# S32K322_M7 register map
Vendor: NXP Semiconductors; File version: 1.0
CPU: CM7 r0p1, little endian, MPU, FPU, VTOR, 4 interrupt priority bits
Registers are 32-bit, read-write, reset 0x0 unless marked. A register's access mark holds for its fields unless they carry their own. Offsets are from the block's base; [hi:lo] are bit positions; {n}, {i} and the like mark numbered series.

## DMAMUX_0 — DMAMUX
Base 0x40280000
Same registers: DMAMUX_1 0x40284000
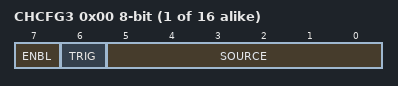
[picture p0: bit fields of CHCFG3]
0x00 CHCFG{x} (x=3,2,1,0,7,6,5,4,11,10,9,8,15,14,13,12; step 0x1) 8-bit — Channel Configuration register
  [7] ENBL — DMA Channel Enable
    0=DISABLE (DMA channel is disabled. This mode is primarily used during configuration of the DMAMUX. The DMA has separate channel enables/disables, which should be used to disable or reconfigure a DMA channel.); 1=ENABLE (DMA channel is enabled)
  [6] TRIG — DMA Channel Trigger Enable
    0=DISABLE (Triggering is disabled. If triggering is disabled and ENBL is set, the DMA Channel will simply route the specified source to the DMA channel. (Normal mode)); 1=ENABLE (Triggering is enabled. If triggering is enabled and ENBL is set, the DMAMUX is in Periodic Trigger mode.)
  [5:0] SOURCE — DMA Channel Source (Slot)

## RTC
Base 0x40288000
0x00 RTCSUPV reset 0x80000000 — RTC Supervisor control register
  [31] SUPV — RTC Supervisor Bit.
    0=All registers are accessible in both user as well as supervisor mode; 1=All other registers are accessible in the supervisor mode only
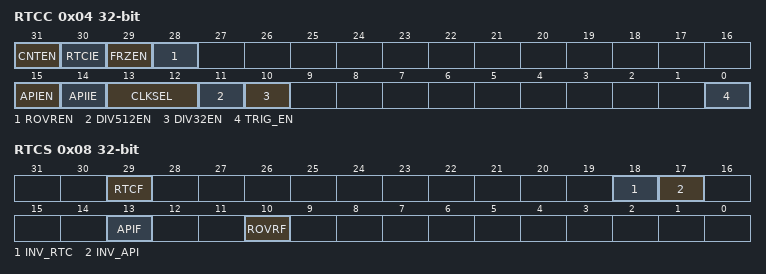
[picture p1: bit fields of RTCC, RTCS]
0x04 RTCC — RTC Control register
  [31] CNTEN — Counter Enable
    0=Counter disabled; 1=Counter enabled
  [30] RTCIE — RTC Interrupt Enable.
    0=RTC interrupts disabled; 1=RTC interrupts enabled
  [29] FRZEN — Freeze Enable Bit
    0=Counter does not freeze in debug mode; 1=Counter freezes in debug mode
  [28] ROVREN — Counter Roll Over wakeup/Interrupt Enable.
    0=RTC rollover wakeup/interrupt disabled; 1=RTC rollover wakeup/interrupt enabled
  [15] APIEN — Autonomous Periodic Interrupt Enable.
    0=API disabled; 1=API enabled
  [14] APIIE — API Interrupt Enable.
    0=API interrupts disabled; 1=API interrupts enabled
  [13:12] CLKSEL — Clock select
    {v}=Clock source {v} (v=0..3)
  [11] DIV512EN — Divide by 512 enable
    0=Divide by 512 is disabled; 1=Divide by 512 is enabled
  [10] DIV32EN — Divide by 32 enable.
    0=Divide by 32 is disabled; 1=Divide by 32 is enabled
  [0] TRIG_EN — Trigger enable for Analog Comparator
0x08 RTCS — RTC Status register
  [29] RTCF write-1-clears — RTC Interrupt Flag
    0=RTC counter is not equal to RTCVAL; 1=RTC counter matches RTCVAL
  [18] INV_RTC ro — Invalid RTC write
  [17] INV_API ro — Invalid APIVAL write
  [13] APIF write-1-clears — API Interrupt Flag.
    0=Counter is not equal to API offset value; 1=Counter matches the API offset value
  [10] ROVRF write-1-clears — Counter Roll Over Interrupt Flag.
    0=RTC has not rolled over; 1=RTC has rolled over
0x0C RTCCNT ro — RTC Counter register
  [31:0] RTCCNT — RTC Counter Value
0x10 APIVAL — API Compare value register
  [31:0] APIVAL — API Compare Value.
0x14 RTCVAL — RTC Compare value register
  [31:0] RTCVAL — RTC Compare Value.

## VIRT_WRAPPER — VIRT_WRAPPER memory map
Base 0x402A8000
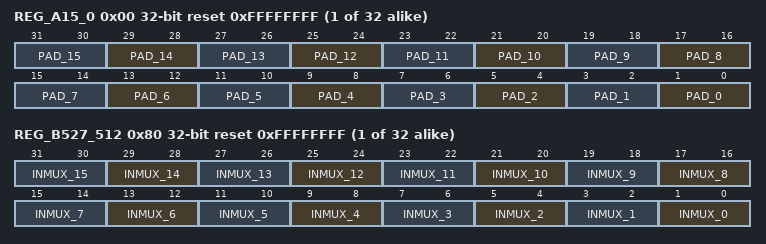
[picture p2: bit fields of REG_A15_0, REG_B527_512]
0x00 REG_A{x} (x=15_0,31_16,47_32,63_48,79_64,95_80,111_96,127_112,143_128,159_144,175_160,191_176,207_192,223_208,239_224,255_240,271_256,287_272,303_288,319_304,335_320,351_336,367_352,383_368,399_384,415_400,431_416,447_432,463_448,479_464,495_480,511_496; step 0x4) reset 0xFFFFFFFF — Parameter_n Register
  [2n+1:2n] PAD_{n} (n=0..15)
0x80 REG_B{x} (x=527_512,543_528,559_544,575_560,591_576,607_592,623_608,639_624,655_640,671_656,687_672,703_688,719_704,735_720,751_736,767_752,783_768,799_784,815_800,831_816,847_832,863_848,879_864,895_880,911_896,927_912,943_928,959_944,975_960,991_976,1007_992,1023_1008; step 0x4) reset 0xFFFFFFFF — Parameter_n Register
  [2n+1:2n] INMUX_{n} (n=0..15)
0x100 REG_C1039_1024 reset 0xFFFFFFFF — Parameter_n Register
  [1:0] INTC_CTRL — Interrupt register control
0x104 REG_D1055_1040 reset 0xFFFFFFFF — Parameter_n Register
  [31:30] REG_GCR — GCR Register Of REG_PROT
